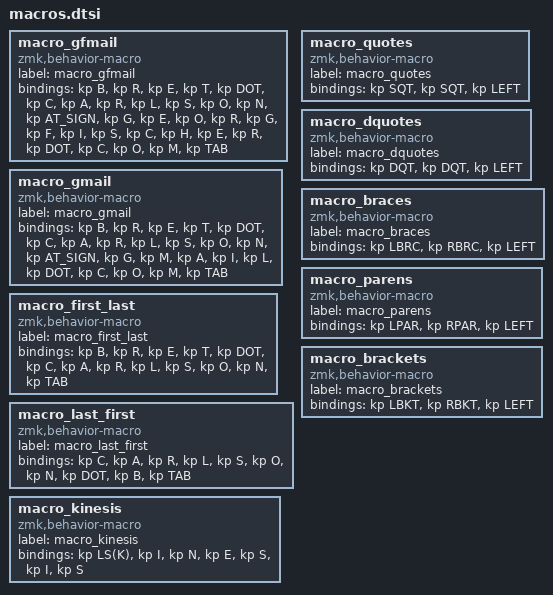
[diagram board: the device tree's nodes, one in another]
  macro_gfmail: macro_gfmail {
    compatible = "zmk,behavior-macro";
    label = "macro_gfmail";
    #binding-cells = <0>;
    bindings = <&kp B &kp R &kp E &kp T &kp DOT &kp C &kp A &kp R &kp L &kp S &kp O &kp N &kp AT_SIGN &kp G &kp E &kp O &kp R &kp G &kp F &kp I &kp S &kp C &kp H &kp E &kp R &kp DOT &kp C &kp O &kp M &kp TAB>;
  };
  macro_gmail: macro_gmail {
    compatible = "zmk,behavior-macro";
    label = "macro_gmail";
    #binding-cells = <0>;
    bindings = <&kp B>, <&kp R>, <&kp E>, <&kp T>, <&kp DOT>, <&kp C>, <&kp A>, <&kp R>, <&kp L>, <&kp S>, <&kp O>, <&kp N>, <&kp AT_SIGN>, <&kp G>, <&kp M>, <&kp A>, <&kp I>, <&kp L>, <&kp DOT>, <&kp C>, <&kp O>, <&kp M>, <&kp TAB>;
  };
  macro_first_last: macro_first_last {
    compatible = "zmk,behavior-macro";
    label = "macro_first_last";
    #binding-cells = <0>;
    bindings = <&kp B>, <&kp R>, <&kp E>, <&kp T>, <&kp DOT>, <&kp C>, <&kp A>, <&kp R>, <&kp L>, <&kp S>, <&kp O>, <&kp N>, <&kp TAB>;
  };
  macro_last_first: macro_last_first {
    compatible = "zmk,behavior-macro";
    label = "macro_last_first";
    #binding-cells = <0>;
    bindings = <&kp C>, <&kp A>, <&kp R>, <&kp L>, <&kp S>, <&kp O>, <&kp N>, <&kp DOT>, <&kp B>, <&kp TAB>;
  };
  macro_quotes: macro_quotes {
    compatible = "zmk,behavior-macro";
    label = "macro_quotes";
    #binding-cells = <0>;
    bindings = <&kp SQT>, <&kp SQT>, <&kp LEFT>;
  };
  macro_dquotes: macro_dquotes {
    compatible = "zmk,behavior-macro";
    label = "macro_dquotes";
    #binding-cells = <0>;
    bindings = <&kp DQT>, <&kp DQT>, <&kp LEFT>;
  };
  macro_braces: macro_braces {
    compatible = "zmk,behavior-macro";
    label = "macro_braces";
    #binding-cells = <0>;
    bindings = <&kp LBRC>, <&kp RBRC>, <&kp LEFT>;
  };
  macro_parens: macro_parens {
    compatible = "zmk,behavior-macro";
    label = "macro_parens";
    #binding-cells = <0>;
    bindings = <&kp LPAR>, <&kp RPAR>, <&kp LEFT>;
  };
  macro_brackets: macro_brackets {
    compatible = "zmk,behavior-macro";
    label = "macro_brackets";
    #binding-cells = <0>;
    bindings = <&kp LBKT>, <&kp RBKT>, <&kp LEFT>;
  };
  macro_kinesis: macro_kinesis {
    compatible = "zmk,behavior-macro";
    label = "macro_kinesis";
    #binding-cells = <0>;
    bindings = <&kp LS(K)>, <&kp I>, <&kp N>, <&kp E>, <&kp S>, <&kp I>, <&kp S>;
  };
